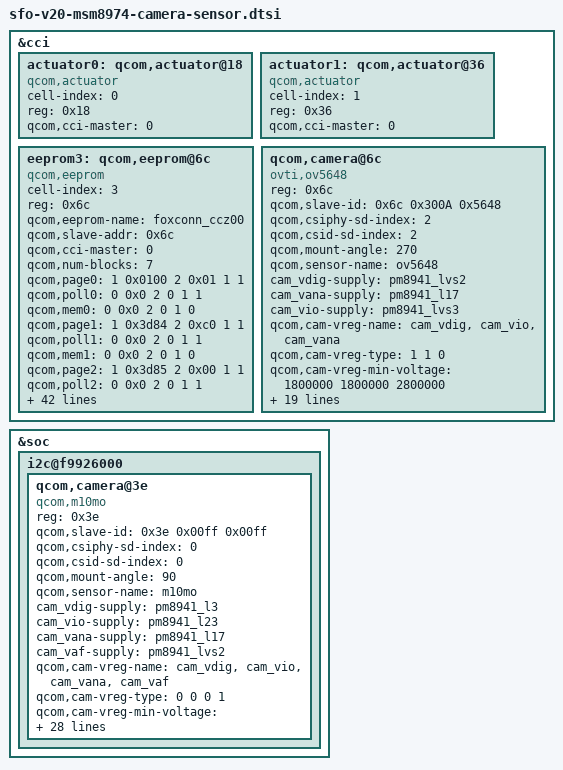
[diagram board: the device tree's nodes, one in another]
/*
 * Copyright (c) 2012-2013, The Linux Foundation. All rights reserved.
 *
 * This program is free software; you can redistribute it and/or modify
 * it under the terms of the GNU General Public License version 2 and
 * only version 2 as published by the Free Software Foundation.
 *
 * This program is distributed in the hope that it will be useful,
 * but WITHOUT ANY WARRANTY; without even the implied warranty of
 * MERCHANTABILITY or FITNESS FOR A PARTICULAR PURPOSE.  See the
 * GNU General Public License for more details.
 */

&cci {

	actuator0: qcom,actuator@18 {
		cell-index = <0>;
		reg = <0x18>;
		compatible = "qcom,actuator";
		qcom,cci-master = <0>;
	};

	actuator1: qcom,actuator@36 {
		cell-index = <1>;
		reg = <0x36>;
		compatible = "qcom,actuator";
		qcom,cci-master = <0>;
	};

	eeprom3: qcom,eeprom@6c {
                cell-index = <3>;
                reg = <0x6c>;
                qcom,eeprom-name = "foxconn_ccz00";
                compatible = "qcom,eeprom";
                qcom,slave-addr = <0x6c>;
                qcom,cci-master = <0>;
                qcom,num-blocks = <7>;
		qcom,page0 = <1 0x0100 2 0x01 1 1>;
                qcom,poll0 = <0 0x0 2 0 1 1>;
                qcom,mem0 = <0 0x0 2 0 1 0>;
                qcom,page1 = <1 0x3d84 2 0xc0 1 1>;
                qcom,poll1 = <0 0x0 2 0 1 1>;
                qcom,mem1 = <0 0x0 2 0 1 0>;
                qcom,page2 = <1 0x3d85 2 0x00 1 1>;
                qcom,poll2 = <0 0x0 2 0 1 1>;
                qcom,mem2 = <0 0x0 2 0 1 0>;
                qcom,page3 = <1 0x3d86 2 0x0f 1 1>;
                qcom,pageen3 = <1 0x3d81 2 0x01 1 10>;
                qcom,poll3 = <0 0x0 2 0 1 1>;
                qcom,mem3 = <16 0x3d00 2 0 1 0>;
                qcom,page4 = <1 0x3d84 2 0xc0 1 1>;
                qcom,poll4 = <0 0x0 2 0 1 1>;
                qcom,mem4 = <0 0x0 2 0 1 0>;
                qcom,page5 = <1 0x3d85 2 0x10 1 1>;
                qcom,poll5 = <0 0x0 2 0 1 1>;
                qcom,mem5 = <0 0x0 2 0 1 0>;
                qcom,page6 = <1 0x3d86 2 0x1f 1 1>;
                qcom,pageen6 = <1 0x3d81 2 0x01 1 10>;
                qcom,poll6 = <0 0x0 2 0 1 1>;
                qcom,mem6 = <16 0x3d00 2 0 1 0>;
		cam_vdig-supply = <&pm8941_lvs2>;
                cam_vana-supply = <&pm8941_l17>;
                cam_vio-supply = <&pm8941_lvs3>;
                qcom,cam-vreg-name = "cam_vdig","cam_vio", "cam_vana";
                qcom,cam-vreg-type = <1 1 0>;
                qcom,cam-vreg-min-voltage = <1800000 1800000 2800000>;
                qcom,cam-vreg-max-voltage = <1800000 1800000 2800000>;
                qcom,cam-vreg-op-mode = <32000 0 34000>;
                qcom,gpio-no-mux = <0>;
                gpios = <&msmgpio 17 0>,
                        <&msmgpio 18 0>,
                        <&msmgpio 92 0>;
                qcom,gpio-reset = <1>;
                qcom,gpio-standby = <2>;
                qcom,gpio-req-tbl-num = <0 1 2>;
                qcom,gpio-req-tbl-flags = <1 0 0>;
                qcom,gpio-req-tbl-label = "CAMIF_MCLK",
                        "CAM_RESET1",
                        "CAM_STANDBY";
                qcom,cam-power-seq-type = "sensor_vreg","sensor_vreg",
                        "sensor_vreg", "sensor_clk",
                        "sensor_gpio", "sensor_gpio";
                qcom,cam-power-seq-val = "cam_vdig","cam_vana",
                        "cam_vio", "sensor_cam_mclk",
                        "sensor_gpio_reset",
                        "sensor_gpio_standby";
                qcom,cam-power-seq-cfg-val = <1 1 1 24000000 1 1>;
                qcom,cam-power-seq-delay = <1 1 1 5 5 10>;
        };


	qcom,camera@6c {
		compatible = "ovti,ov5648";
		reg = <0x6c>;
		qcom,slave-id = <0x6c 0x300A 0x5648>;
		qcom,csiphy-sd-index = <2>;
		qcom,csid-sd-index = <2>;
		qcom,mount-angle = <270>;
		qcom,sensor-name = "ov5648";
		cam_vdig-supply = <&pm8941_lvs2>;
		cam_vana-supply = <&pm8941_l17>;
		cam_vio-supply = <&pm8941_lvs3>;
		qcom,cam-vreg-name = "cam_vdig", "cam_vio", "cam_vana";
		qcom,cam-vreg-type = <1 1 0>;
		qcom,cam-vreg-min-voltage = <1800000 1800000 2800000>;
		qcom,cam-vreg-max-voltage = <1800000 1800000 2800000>;
		qcom,cam-vreg-op-mode = <32000 0 34000>;
		qcom,gpio-no-mux = <0>;
		gpios = <&msmgpio 17 0>,
			<&msmgpio 18 0>,
			<&msmgpio 92 0>;
		qcom,gpio-reset = <1>;
		qcom,gpio-standby = <2>;
		qcom,gpio-req-tbl-num = <0 1 2>;
		qcom,gpio-req-tbl-flags = <1 0 0>;
		qcom,gpio-req-tbl-label = "CAMIF_MCLK",
					  "CAM_RESET1",
					  "CAM_STANDBY";
		qcom,gpio-set-tbl-num = <1 1>;
		qcom,gpio-set-tbl-flags = <0 2>;
		qcom,gpio-set-tbl-delay = <1000 4000>;
		qcom,csi-lane-assign = <0x4320>;
		qcom,csi-lane-mask = <0x7>;
		qcom,sensor-position = <1>;
		qcom,sensor-mode = <1>;
		qcom,cci-master = <0>;
		status = "ok";
	};
};

&soc {
    i2c@f9926000 {
		qcom,camera@3e {
		compatible = "qcom,m10mo";
		reg = <0x3e>;
		qcom,slave-id = <0x3e 0x00ff 0x00ff>;
		qcom,csiphy-sd-index = <0>;
		qcom,csid-sd-index = <0>;
		qcom,mount-angle = <90>;
		qcom,sensor-name = "m10mo";
		cam_vdig-supply = <&pm8941_l3>;
		cam_vio-supply = <&pm8941_l23>;
		cam_vana-supply = <&pm8941_l17>;
		cam_vaf-supply = <&pm8941_lvs2>;
		qcom,cam-vreg-name = "cam_vdig", "cam_vio",
				     "cam_vana", "cam_vaf";
		qcom,cam-vreg-type = <0 0 0 1>;
		qcom,cam-vreg-min-voltage = <1000000 2800000 2800000 1800000>;
		qcom,cam-vreg-max-voltage = <1000000 2800000 2800000 1800000>;
		qcom,cam-vreg-op-mode = <105000 80000 100000 0>;
		qcom,gpio-no-mux = <0>;
		gpios = <&msmgpio 46 0>,
			<&msmgpio 95 0>,
			<&msmgpio 48 0>,
			<&msmgpio 53 0>,
			<&msmgpio 132 0>,
			<&msmgpio 2 0>,
			<&msmgpio 65 0>;
		qcom,gpio-vio = <0>;
		qcom,gpio-reset = <1>;
		qcom,gpio-vana = <2>;
		qcom,gpio-vdig = <3>;
		qcom,gpio-interrupt = <4>;
		qcom,gpio-sio-cs = <5>;
		qcom,gpio-mod-id = <6>;
		qcom,gpio-req-tbl-num = <0 1 2 3 4 5 6>;
		qcom,gpio-req-tbl-flags = <0 0 0 0 2 0 2>;
		qcom,gpio-req-tbl-label = "CAM_VIO",
					  "CAM_RESET1",
					  "CAM_VANA",
					  "CAM_VDIG",
					  "CAM_INT",
					  "CAM_SIO_CS",
					  "CAM_MOD_ID";
		qcom,gpio-set-tbl-num = <1 1 5>;
		qcom,gpio-set-tbl-flags = <0 2 0>;
		qcom,gpio-set-tbl-delay = <1000 30000 1000>;
		qcom,csi-lane-assign = <0x4320>;
		qcom,csi-lane-mask = <0x1F>;
		qcom,sensor-position = <0>;
		qcom,sensor-mode = <0>;
		qcom,sensor-type = <1>;
		status = "ok";
	};
    };
};
